# regs-internal register map
Registers are 32-bit, access not given, no defined reset value unless marked. A register's access mark holds for its fields unless they carry their own. Addresses are absolute; registers are grouped by the start of their names; [hi:lo] are bit positions; {n}, {i} and the like mark numbered series; 'fields as' and 'values as' point back to an identical list.

## TMR2
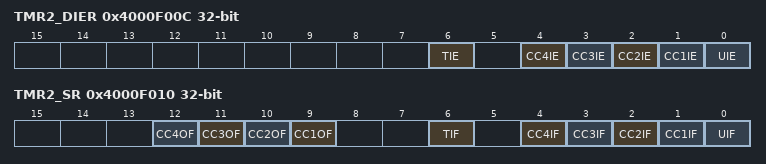
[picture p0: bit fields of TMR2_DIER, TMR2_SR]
0x4000F00C TMR2_DIER
  [6] TIE, [n] CC{n}IE (n=1..4), [0] UIE
0x4000F010 TMR2_SR
  [n+8] CC{n}OF (n=1..4), [6] TIF, [n] CC{n}IF (n=1..4), [0] UIF

## ITM
{0xE0000000+4i} ITM_SP{i} (i=0..31)
  [0] FIFOREADY, [31:0] STIMULUS
0xE0000E00 ITM_TER
  [31:0] STIMENA
0xE0000E40 ITM_TPR
  [3:0] PRIVMASK
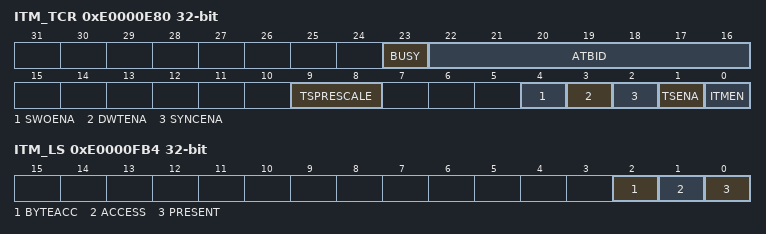
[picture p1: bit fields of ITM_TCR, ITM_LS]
0xE0000E80 ITM_TCR
  [23] BUSY, [22:16] ATBID, [9:8] TSPRESCALE, [4] SWOENA, [3] DWTENA, [2] SYNCENA, [1] TSENA, [0] ITMEN
0xE0000EF8 ITM_IW
  [0] ATVALIDM
0xE0000EFC ITM_IR
  [0] ATREADYM
0xE0000F00 ITM_IMC
  [0] INTEGRATION
0xE0000FB0 ITM_LA
  [31:0] LOCKACC
0xE0000FB4 ITM_LS
  [2] BYTEACC, [1] ACCESS, [0] PRESENT
{0xE0000FC0+4i} ITM_PERIPHID{i} (i=4..7)
  [31:0] PERIPHID
{0xE0000FE0+4i} ITM_PERIPHID{i} (i=0..3)
  [31:0] PERIPHID
{0xE0000FF0+4i} ITM_CELLID{i} (i=0..3)
  [31:0] PERIPHID

## DWT
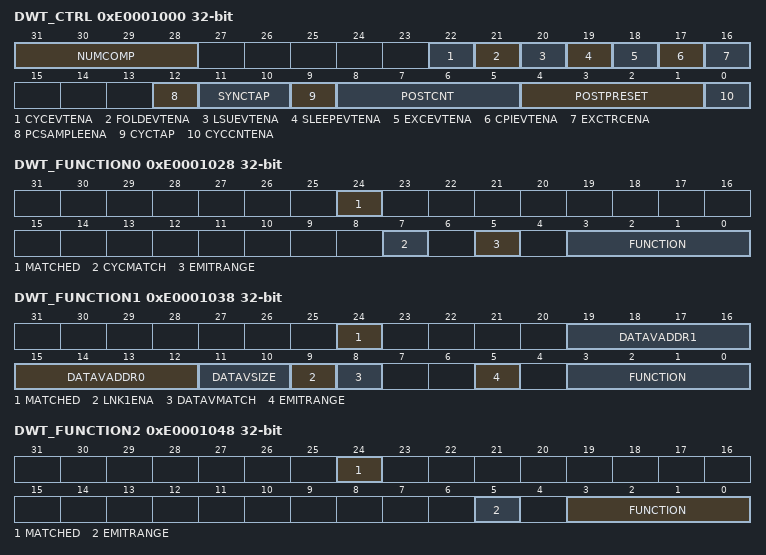
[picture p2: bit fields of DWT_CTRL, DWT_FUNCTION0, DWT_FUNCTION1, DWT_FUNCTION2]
0xE0001000 DWT_CTRL
  [31:28] NUMCOMP, [22] CYCEVTENA, [21] FOLDEVTENA, [20] LSUEVTENA, [19] SLEEPEVTENA, [18] EXCEVTENA, [17] CPIEVTENA, [16] EXCTRCENA, [12] PCSAMPLEENA, [11:10] SYNCTAP, [9] CYCTAP, [8:5] POSTCNT, [4:1] POSTPRESET, [0] CYCCNTENA
0xE0001004 DWT_CYCCNT
0xE0001008 DWT_CPICNT
  [7:0] CPICNT
0xE000100C DWT_EXCCNT
  [7:0] EXCCNT
0xE0001010 DWT_SLEEPCNT
  [7:0] SLEEPCNT
0xE0001014 DWT_LSUCNT
  [7:0] CPICNT
0xE0001018 DWT_FOLDCNT
  [7:0] CPICNT
0xE000101C DWT_PCSR
  [31:0] EIASAMPLE
{0xE0001020+0x10*i} DWT_COMP{i} (i=0..3)
{0xE0001024+0x10*i} DWT_MASK{i} (i=0..3)
  [4:0] MASK{i}
0xE0001028 DWT_FUNCTION0
  [24] MATCHED, [7] CYCMATCH, [5] EMITRANGE, [3:0] FUNCTION
0xE0001038 DWT_FUNCTION1
  [24] MATCHED, [19:16] DATAVADDR1, [15:12] DATAVADDR0, [11:10] DATAVSIZE, [9] LNK1ENA, [8] DATAVMATCH, [5] EMITRANGE, [3:0] FUNCTION
0xE0001048 DWT_FUNCTION2
  [24] MATCHED, [5] EMITRANGE, [3:0] FUNCTION
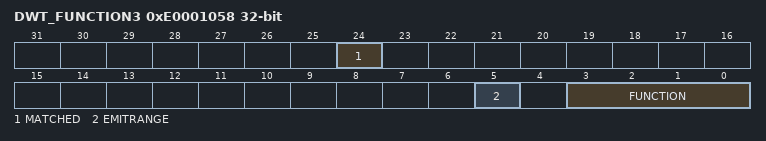
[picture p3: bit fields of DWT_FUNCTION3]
0xE0001058 DWT_FUNCTION3
  [24] MATCHED, [5] EMITRANGE, [3:0] FUNCTION
{0xE0001FC0+4i} DWT_PERIPHID{i} (i=4..7)
  [31:0] PERIPHID
{0xE0001FE0+4i} DWT_PERIPHID{i} (i=0..3)
  [31:0] PERIPHID
{0xE0001FF0+4i} DWT_CELLID{i} (i=0..3)
  [31:0] CELLID

## FPB
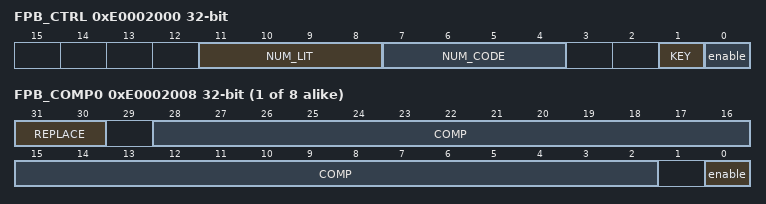
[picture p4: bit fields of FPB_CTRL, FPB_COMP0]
0xE0002000 FPB_CTRL
  [11:8] NUM_LIT, [7:4] NUM_CODE, [1] KEY, [0] enable
0xE0002004 FPB_REMAP
  [28:5] REMAP
{0xE0002008+4i} FPB_COMP{i} (i=0..7)
  [31:30] REPLACE, [28:2] COMP, [0] enable
{0xE0002FC0+4i} FPB_PERIPHID{i} (i=4..7)
  [31:0] PERIPHID
{0xE0002FE0+4i} FPB_PERIPHID{i} (i=0..3)
  [31:0] PERIPHID
{0xE0002FF0+4i} FPB_CELLID{i} (i=0..3)
  [31:0] CELLID

## NVIC
0xE000E000 NVIC_MCR
0xE000E004 NVIC_ICTR
  [4:0] INTLINESNUM
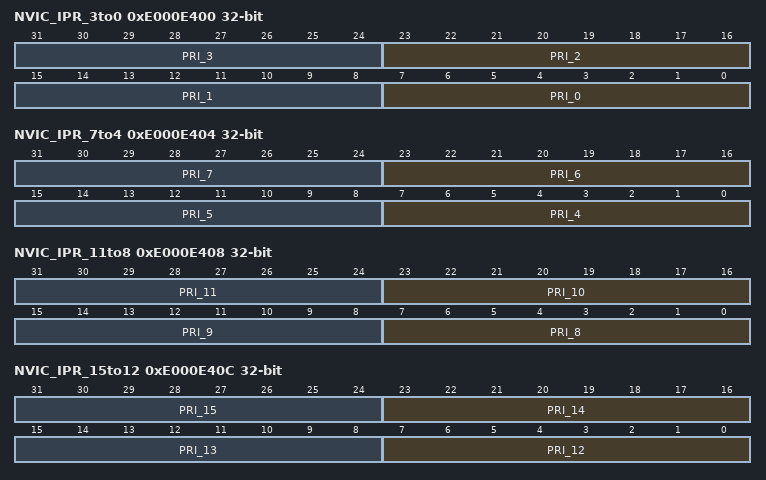
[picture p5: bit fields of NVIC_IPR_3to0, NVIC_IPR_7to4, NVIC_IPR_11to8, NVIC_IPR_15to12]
0xE000E400 NVIC_IPR_3to0
  [8n+7:8n] PRI_{n} (n=0..3)
0xE000E404 NVIC_IPR_7to4
  [8n-25:8n-32] PRI_{n} (n=4..7)
0xE000E408 NVIC_IPR_11to8
  [8n-57:8n-64] PRI_{n} (n=8..11)
0xE000E40C NVIC_IPR_15to12
  [8n-89:8n-96] PRI_{n} (n=12..15)
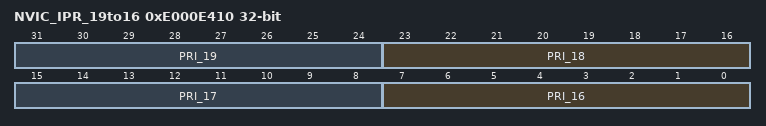
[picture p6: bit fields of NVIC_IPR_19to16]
0xE000E410 NVIC_IPR_19to16
  [8n-121:8n-128] PRI_{n} (n=16..19)
0xE000EF00 NVIC_STIR
  [9:0] INTID
{0xE000EFC0+4i} NVIC_PERIPHID{i} (i=4..7)
  [31:0] PERIPHID
{0xE000EFE0+4i} NVIC_PERIPHID{i} (i=0..3)
  [31:0] PERIPHID
{0xE000EFF0+4i} NVIC_PCELLID{i} (i=0..3)
  [31:0] PCELLID

## ST
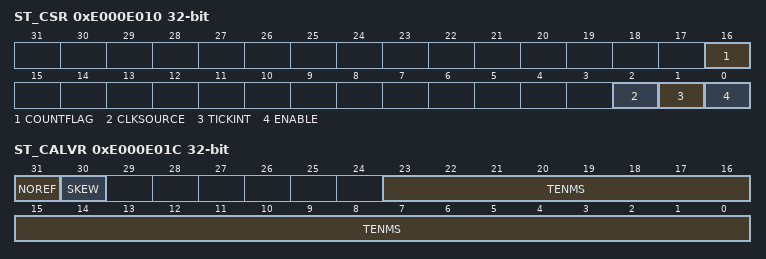
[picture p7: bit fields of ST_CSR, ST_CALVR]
0xE000E010 ST_CSR
  [16] COUNTFLAG, [2] CLKSOURCE, [1] TICKINT, [0] ENABLE
0xE000E014 ST_RVR
  [23:0] RELOAD
0xE000E018 ST_CVR
  [31:0] CURRENT
0xE000E01C ST_CALVR
  [31] NOREF, [30] SKEW, [23:0] TENMS

## SCS
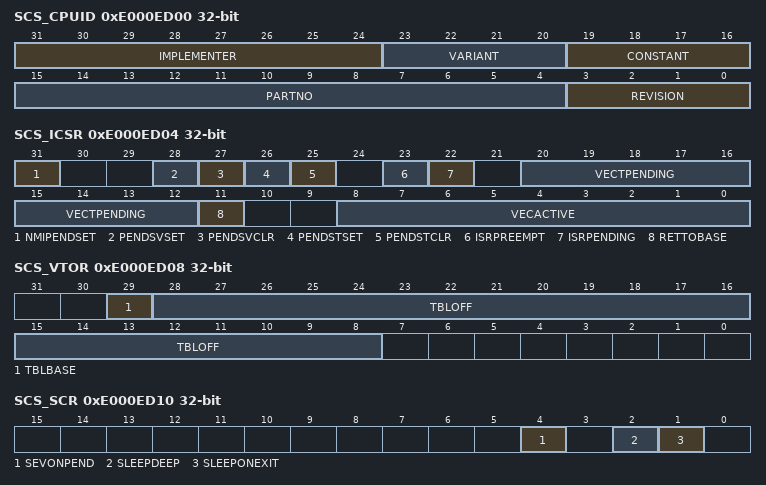
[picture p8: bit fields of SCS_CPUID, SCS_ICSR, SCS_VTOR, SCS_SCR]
0xE000ED00 SCS_CPUID
  [31:24] IMPLEMENTER, [23:20] VARIANT, [19:16] CONSTANT, [15:4] PARTNO, [3:0] REVISION
0xE000ED04 SCS_ICSR
  [31] NMIPENDSET, [28] PENDSVSET, [27] PENDSVCLR, [26] PENDSTSET, [25] PENDSTCLR, [23] ISRPREEMPT, [22] ISRPENDING, [20:12] VECTPENDING, [11] RETTOBASE, [8:0] VECACTIVE
0xE000ED08 SCS_VTOR
  [29] TBLBASE, [28:8] TBLOFF
0xE000ED0C SCS_AIRCR
  [31:16] VECTKEYSTAT, [31:16] VECTKEY, [15] ENDIANESS, [10:8] PRIGROUP, [2] SYSRESETREQ, [1] VECTCLRACTIVE, [0] VECTRESET
0xE000ED10 SCS_SCR
  [4] SEVONPEND, [2] SLEEPDEEP, [1] SLEEPONEXIT
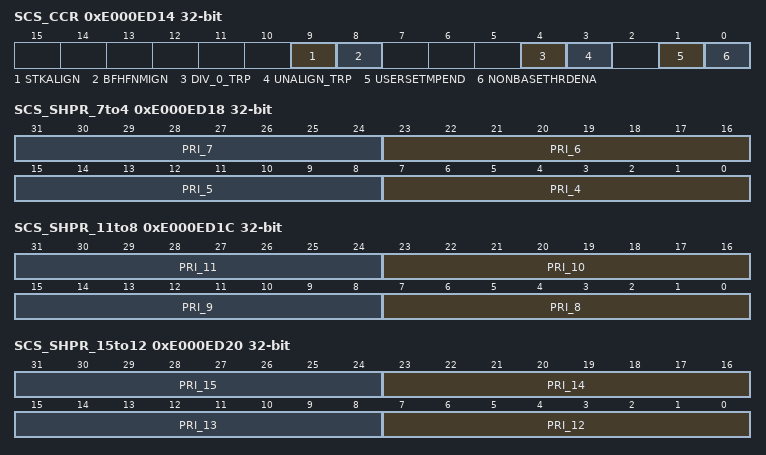
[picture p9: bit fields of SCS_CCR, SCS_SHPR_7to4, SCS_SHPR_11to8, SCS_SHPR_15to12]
0xE000ED14 SCS_CCR
  [9] STKALIGN, [8] BFHFNMIGN, [4] DIV_0_TRP, [3] UNALIGN_TRP, [1] USERSETMPEND, [0] NONBASETHRDENA
0xE000ED18 SCS_SHPR_7to4
  [8n-25:8n-32] PRI_{n} (n=4..7)
0xE000ED1C SCS_SHPR_11to8
  [8n-57:8n-64] PRI_{n} (n=8..11)
0xE000ED20 SCS_SHPR_15to12
  [8n-89:8n-96] PRI_{n} (n=12..15)
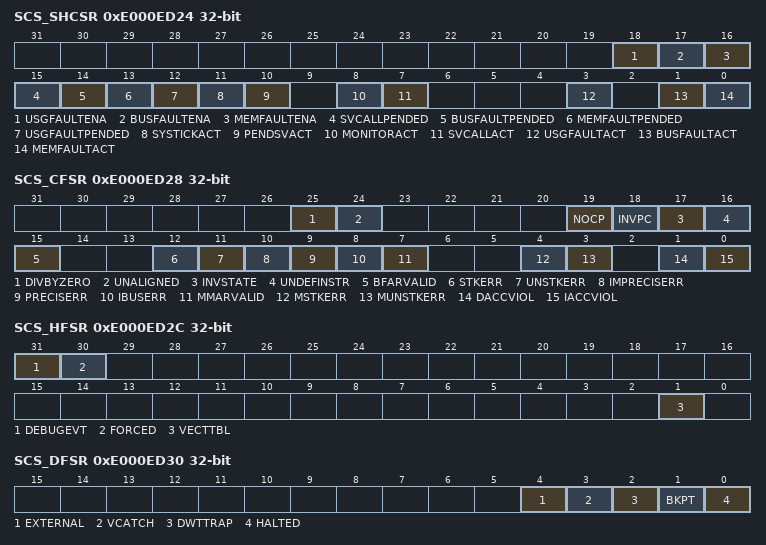
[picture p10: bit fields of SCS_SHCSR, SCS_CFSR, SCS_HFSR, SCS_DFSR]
0xE000ED24 SCS_SHCSR
  [18] USGFAULTENA, [17] BUSFAULTENA, [16] MEMFAULTENA, [15] SVCALLPENDED, [14] BUSFAULTPENDED, [13] MEMFAULTPENDED, [12] USGFAULTPENDED, [11] SYSTICKACT, [10] PENDSVACT, [8] MONITORACT, [7] SVCALLACT, [3] USGFAULTACT, [1] BUSFAULTACT, [0] MEMFAULTACT
0xE000ED28 SCS_CFSR
  [25] DIVBYZERO, [24] UNALIGNED, [19] NOCP, [18] INVPC, [17] INVSTATE, [16] UNDEFINSTR, [15] BFARVALID, [12] STKERR, [11] UNSTKERR, [10] IMPRECISERR, [9] PRECISERR, [8] IBUSERR, [7] MMARVALID, [4] MSTKERR, [3] MUNSTKERR, [1] DACCVIOL, [0] IACCVIOL
0xE000ED2C SCS_HFSR
  [31] DEBUGEVT, [30] FORCED, [1] VECTTBL
0xE000ED30 SCS_DFSR
  [4] EXTERNAL, [3] VCATCH, [2] DWTTRAP, [1] BKPT, [0] HALTED
0xE000ED34 SCS_MMAR
  [31:0] ADDRESS
0xE000ED38 SCS_BFAR
  [31:0] ADDRESS
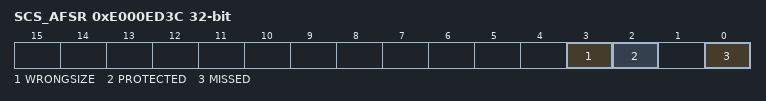
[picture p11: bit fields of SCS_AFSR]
0xE000ED3C SCS_AFSR
  [3] WRONGSIZE, [2] PROTECTED, [0] MISSED
0xE000ED40 SCS_PFR0
  [31:0] FEATURE
0xE000ED44 SCS_PFR1
  [31:0] FEATURE
0xE000ED48 SCS_DFR0
  [31:0] FEATURE
0xE000ED4C SCS_AFR0
  [31:0] FEATURE
{0xE000ED50+4i} SCS_MMFR{i} (i=0..3)
  [31:0] FEATURE
{0xE000ED60+4i} SCS_ISAFR{i} (i=0..4)
  [31:0] FEATURE

## MPU
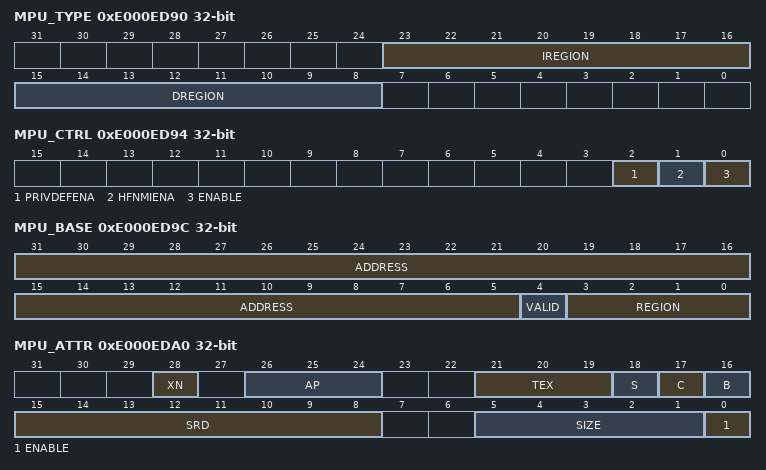
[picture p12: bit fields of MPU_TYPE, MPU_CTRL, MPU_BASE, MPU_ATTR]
0xE000ED90 MPU_TYPE
  [23:16] IREGION, [15:8] DREGION
0xE000ED94 MPU_CTRL
  [2] PRIVDEFENA, [1] HFNMIENA, [0] ENABLE
0xE000ED98 MPU_REGION
  [7:0] REGION
0xE000ED9C MPU_BASE
  [31:5] ADDRESS, [4] VALID, [3:0] REGION
0xE000EDA0 MPU_ATTR
  [28] XN, [26:24] AP, [21:19] TEX, [18] S, [17] C, [16] B, [15:8] SRD, [5:1] SIZE, [0] ENABLE
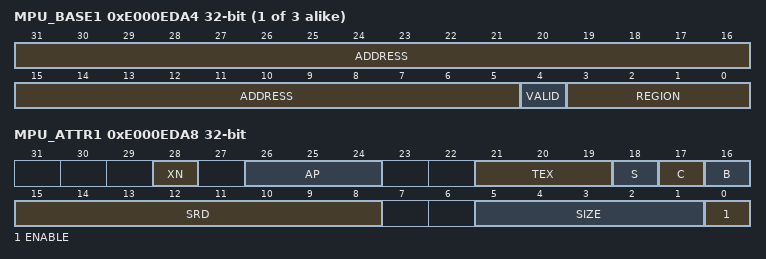
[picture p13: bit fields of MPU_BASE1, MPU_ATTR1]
{0xE000ED9C+8i} MPU_BASE{i} (i=1..3)
  [31:5] ADDRESS, [4] VALID, [3:0] REGION
0xE000EDA8 MPU_ATTR1
  fields as MPU_ATTR
0xE000EDB0 MPU_ATTR2
  [28] XN, [28:24] AP, [21:19] TEX, [18] S, [17] C, [16] B, [15:8] SRD, [5:1] SIZE, [1:0] ENABLE
0xE000EDBC MPU_ATTR3
  fields as MPU_ATTR2

## TPIU
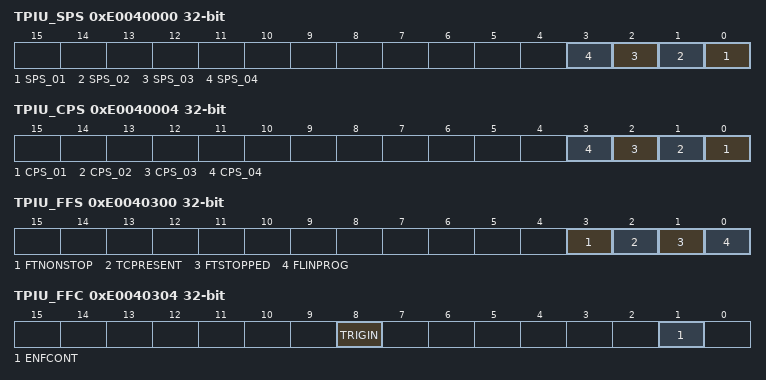
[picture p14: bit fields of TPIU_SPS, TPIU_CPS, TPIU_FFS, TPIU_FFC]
0xE0040000 TPIU_SPS
  [n-1] SPS_{n:02} (n=1..4)
0xE0040004 TPIU_CPS
  [n-1] CPS_{n:02} (n=1..4)
0xE0040010 TPIU_COSD
  [12:0] PRESCALER
0xE00400F0 TPIU_SPP
  [1:0] PROTOCOL
0xE0040300 TPIU_FFS
  [3] FTNONSTOP, [2] TCPRESENT, [1] FTSTOPPED, [0] FLINPROG
0xE0040304 TPIU_FFC
  [8] TRIGIN, [1] ENFCONT
0xE0040308 TPIU_FSC
0xE0040EF0 TPIU_ITATBCTR2
  [0] ATREADY1
0xE0040EF8 TPIU_ITATBCTR0
  [0] ATREADY1

## ROM
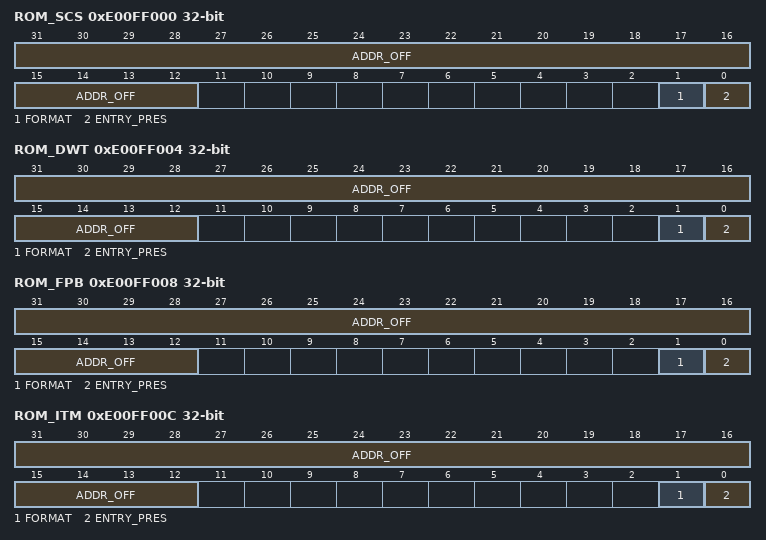
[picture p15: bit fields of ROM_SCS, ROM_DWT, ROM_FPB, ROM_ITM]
0xE00FF000 ROM_SCS
  [31:12] ADDR_OFF, [1] FORMAT, [0] ENTRY_PRES
0xE00FF004 ROM_DWT
  [31:12] ADDR_OFF, [1] FORMAT, [0] ENTRY_PRES
0xE00FF008 ROM_FPB
  [31:12] ADDR_OFF, [1] FORMAT, [0] ENTRY_PRES
0xE00FF00C ROM_ITM
  [31:12] ADDR_OFF, [1] FORMAT, [0] ENTRY_PRES
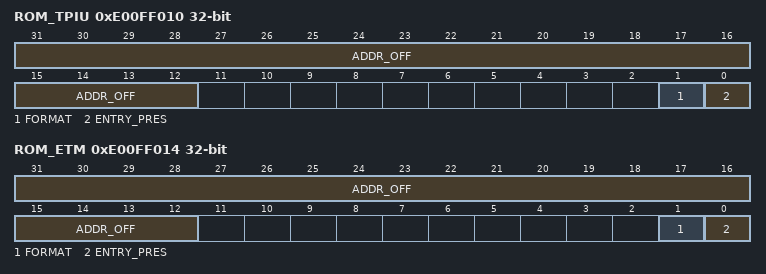
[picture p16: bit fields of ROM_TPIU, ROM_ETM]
0xE00FF010 ROM_TPIU
  [31:12] ADDR_OFF, [1] FORMAT, [0] ENTRY_PRES
0xE00FF014 ROM_ETM
  [31:12] ADDR_OFF, [1] FORMAT, [0] ENTRY_PRES
0xE00FF018 ROM_END
0xE00FFFCC ROM_MEMTYPE
  [0] MEMTYPE
{0xE00FFFC0+4i} ROM_PID{i} (i=4..7)
  [3:0] PID
{0xE00FFFE0+4i} ROM_PID{i} (i=0..3)
  [3:0] PID
{0xE00FFFF0+4i} ROM_CID{i} (i=0..3)
  [7:0] CID
